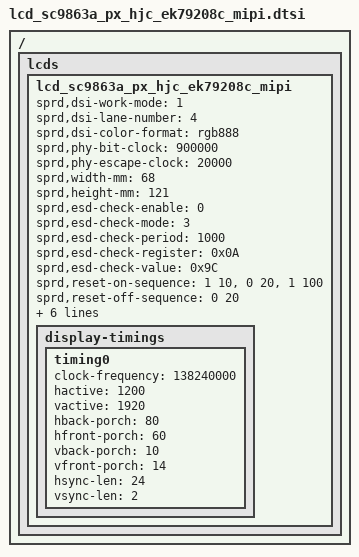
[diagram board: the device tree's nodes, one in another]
/ { lcds {
	lcd_sc9863a_px_hjc_ek79208c_mipi: lcd_sc9863a_px_hjc_ek79208c_mipi {

		sprd,dsi-work-mode = <1>;
		sprd,dsi-lane-number = <4>;
		sprd,dsi-color-format = "rgb888";

		sprd,phy-bit-clock = <900000>;
		sprd,phy-escape-clock = <20000>;

		sprd,width-mm = <68>;
		sprd,height-mm = <121>;

		sprd,esd-check-enable = <0>;
		sprd,esd-check-mode = <3>;
		sprd,esd-check-period = <1000>;
		sprd,esd-check-register = <0x0A>;
		sprd,esd-check-value = <0x9C>;

		sprd,reset-on-sequence = <1 10>, <0 20>, <1 100>;
		sprd,reset-off-sequence = <0 20>;

		sprd,initial-command = [
		
23  00  00  02  B0  0F 

23  00  00  02  CD  AA 

23  00  00  02  30  00 

23  00  00  02  32  00 

23  00  00  02  3A  8F 

23  00  00  02  3D  60 

23  00  00  02  3F  1F 

23  00  00  02  40  0F 

23  00  00  02  30  01 

23  00  00  02  00  01 

23  00  00  02  31  66 

23  00  00  02  32  10 

23  00  00  02  33  74 

23  00  00  02  35  00 

23  00  00  02  36  01 

39  00  00  0D  3A  00  00  10  10  00  00  10  10  00  00  10  10 

39  00  00  0C  3B  22  19  1D  23  23  21  20  17  15  13  11 

39  00  00  0B  3C  0F  0D  0B  09  05  01  23  23  23  00 

39  00  00  0C  3D  22  18  1C  23  23  21  20  16  14  12  10 

39  00  00  0B  3E  0E  0C  0A  08  04  00  23  23  23  00 

23  00  00  02  3F  01 

23  00  00  02  40  B8 

23  00  00  02  41  01 

23  00  00  02  46  87 

23  00  00  02  30  02 

39  00  00  0B  3A  3E  30  2C  2A  33  32  31  33  38  3B 

39  00  00  08  3B  39  37  35  29  1A  0D  00 

39  00  00  0B  3C  3E  30  2C  2A  33  32  31  33  38  3B 

39  00  00  08  3D  39  37  35  29  1A  0D  00 

23  00  00  02  30  07 

23  00  00  02  35  B8 

23  00  00  02  30  08 

23  00  00  02  5C  20 

23  00  00  02  5D  00 

23  00  00  02  30  0A 

23  00  00  02  39  05 

23  00  00  02  3A  1D 

23  00  00  02  4C  04 

23  00  00  02  30  08 

23  00  00  02  33  12 

23  00  00  02  30  01 

23  00  00  02  37  66 

23  00  00  02  30  05 

23  00  00  02  31  19 

23  00  00  02  30  0F 

23  78  00  02  11  00
23  64  00  02  29  00	


			];
		sprd,sleep-in-command = [
			13 0A 00 01 28
			13 78 00 01 10
			];
		sprd,sleep-out-command = [
			13 78 00 01 11
			13 64 00 01 29
			];

		display-timings {
			timing0 {
			clock-frequency = <138240000>;
			hactive = <1200>;
			vactive = <1920>;
			hback-porch = <80>;
			hfront-porch = <60>;
			vback-porch = <10>;
			vfront-porch = <14>;
			hsync-len = <24>;
			vsync-len = <2>;
			};
		};
	};
};};

